# HC32F558 register map
File version: 1.0
CPU: CM4 r0p1, little endian, MPU, FPU, 4 interrupt priority bits
Registers are 32-bit, read-write, reset 0x0 unless marked. A register's access mark holds for its fields unless they carry their own. Offsets are from the block's base; [hi:lo] are bit positions; {n}, {i} and the like mark numbered series.

## RMU
Base 0x4004CC00
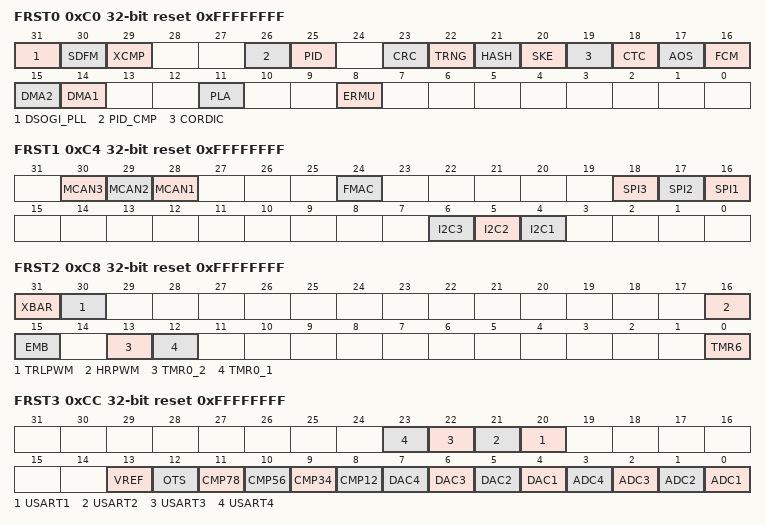
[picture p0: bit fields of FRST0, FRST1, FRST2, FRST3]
0xC0 FRST0 reset 0xFFFFFFFF
  [31] DSOGI_PLL, [30] SDFM, [29] XCMP, [26] PID_CMP, [25] PID, [23] CRC, [22] TRNG, [21] HASH, [20] SKE, [19] CORDIC, [18] CTC, [17] AOS, [16] FCM, [15] DMA2, [14] DMA1, [11] PLA, [8] ERMU
0xC4 FRST1 reset 0xFFFFFFFF
  [30] MCAN3, [29] MCAN2, [28] MCAN1, [24] FMAC, [18] SPI3, [17] SPI2, [16] SPI1, [6] I2C3, [5] I2C2, [4] I2C1
0xC8 FRST2 reset 0xFFFFFFFF
  [31] XBAR, [30] TRLPWM, [16] HRPWM, [15] EMB, [13] TMR0_2, [12] TMR0_1, [0] TMR6
0xCC FRST3 reset 0xFFFFFFFF
  [n+19] USART{n} (n=1..4), [13] VREF, [12] OTS, [11] CMP78, [10] CMP56, [9] CMP34, [8] CMP12, [n+3] DAC{n} (n=1..4), [n-1] ADC{n} (n=1..4)
0xF8 PRSTCR0 8-bit reset 0x40
  [5] LKUPREN
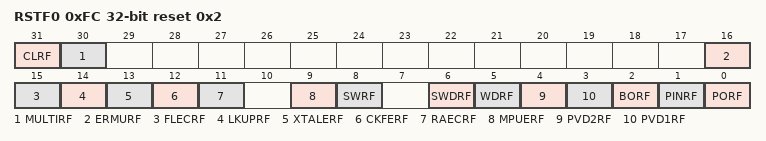
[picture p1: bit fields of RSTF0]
0xFC RSTF0 reset 0x2
  [31] CLRF, [30] MULTIRF, [16] ERMURF, [15] FLECRF, [14] LKUPRF, [13] XTALERF, [12] CKFERF, [11] RAECRF, [9] MPUERF, [8] SWRF, [6] SWDRF, [5] WDRF, [4] PVD2RF, [3] PVD1RF, [2] BORF, [1] PINRF, [0] PORF

## SKE
Base 0x4000E000
0x00 CTRL
  [0] START
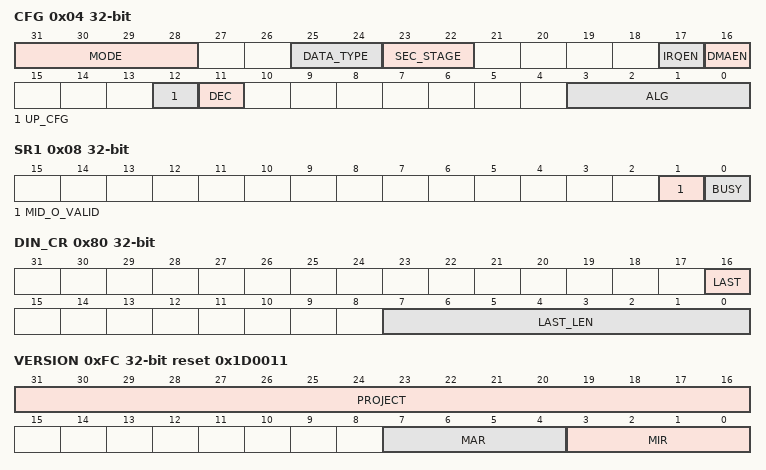
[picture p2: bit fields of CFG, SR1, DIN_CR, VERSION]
0x04 CFG
  [31:28] MODE, [25:24] DATA_TYPE, [23:22] SEC_STAGE, [17] IRQEN, [16] DMAEN, [12] UP_CFG, [11] DEC, [3:0] ALG
0x08 SR1
  [1] MID_O_VALID, [0] BUSY ro
0x0C SR2
  [0] CORE_DONE
{0xC+4i} KEY{i} wo (i=1..8)
0x60 AAD1
0x64 AAD2
0x68 CLEN1
0x6C CLEN2
{0x6C+4i} IV{i} (i=1..4)
0x80 DIN_CR
  [16] LAST, [7:0] LAST_LEN
{0x8C+4i} DIN{i} wo (i=1..4)
{0xAC+4i} DOUT{i} ro (i=1..4)
0xFC VERSION ro reset 0x1D0011
  [31:16] PROJECT, [7:4] MAR, [3:0] MIR
{0x19C+4i} MID_IV{i} (i=1..4)
{0x1AC+4i} MID_MAC{i} (i=1..4)
0x1C0 TOTAL_AAD1
0x1C4 TOTAL_AAD2
0x1C8 TOTAL_CLEN1
0x1CC TOTAL_CLEN2

## SPI1 — desc SPI
Base 0x4001C000
Same registers: SPI2 0x4001C400, SPI3 0x4001C800
0x00 DR
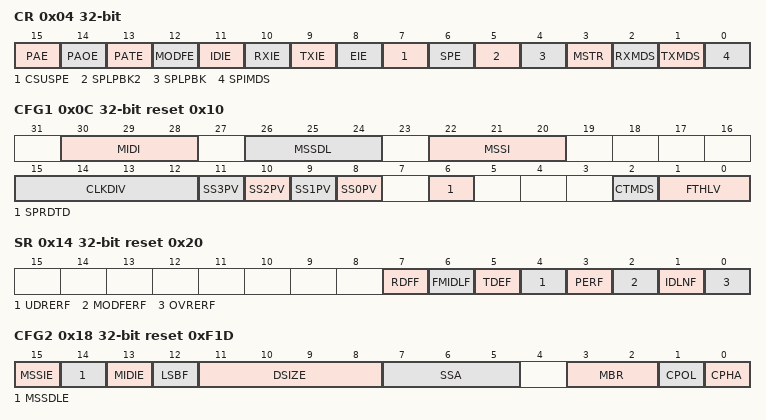
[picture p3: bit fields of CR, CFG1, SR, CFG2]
0x04 CR
  [15] PAE, [14] PAOE, [13] PATE, [12] MODFE, [11] IDIE, [10] RXIE, [9] TXIE, [8] EIE, [7] CSUSPE, [6] SPE, [5] SPLPBK2, [4] SPLPBK, [3] MSTR, [2] RXMDS, [1] TXMDS, [0] SPIMDS
0x0C CFG1 reset 0x10
  [30:28] MIDI, [26:24] MSSDL, [22:20] MSSI, [15:12] CLKDIV, [n+8] SS{n}PV (n=0..3), [6] SPRDTD, [2] CTMDS, [1:0] FTHLV
0x14 SR reset 0x20
  [7] RDFF ro, [6] FMIDLF ro, [5] TDEF ro, [4] UDRERF, [3] PERF, [2] MODFERF, [1] IDLNF ro, [0] OVRERF
0x18 CFG2 reset 0xF1D
  [15] MSSIE, [14] MSSDLE, [13] MIDIE, [12] LSBF, [11:8] DSIZE, [7:5] SSA, [3:2] MBR, [1] CPOL, [0] CPHA

## SRAMC
Base 0x40050800
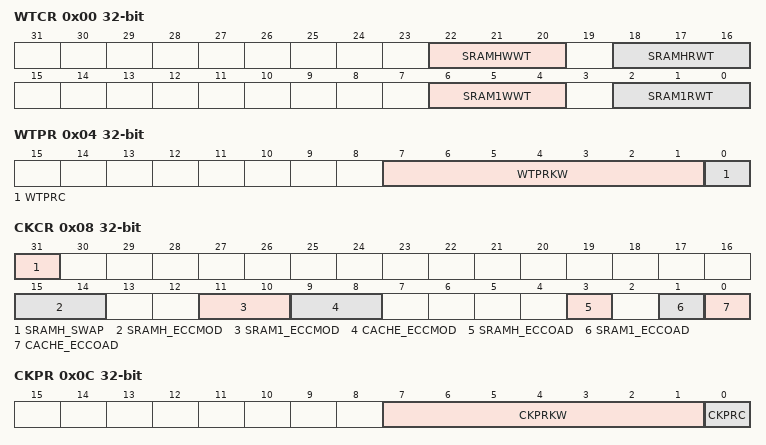
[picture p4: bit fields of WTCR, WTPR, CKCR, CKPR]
0x00 WTCR
  [22:20] SRAMHWWT, [18:16] SRAMHRWT, [6:4] SRAM1WWT, [2:0] SRAM1RWT
0x04 WTPR
  [7:1] WTPRKW, [0] WTPRC
0x08 CKCR
  [31] SRAMH_SWAP, [15:14] SRAMH_ECCMOD, [11:10] SRAM1_ECCMOD, [9:8] CACHE_ECCMOD, [3] SRAMH_ECCOAD, [1] SRAM1_ECCOAD, [0] CACHE_ECCOAD
0x0C CKPR
  [7:1] CKPRKW, [0] CKPRC
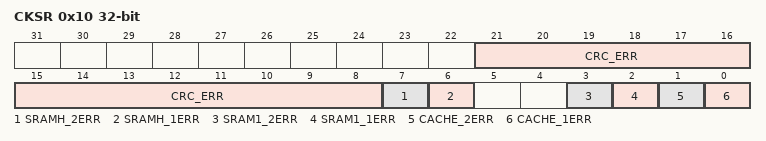
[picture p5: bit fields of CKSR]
0x10 CKSR
  [21:8] CRC_ERR, [7] SRAMH_2ERR, [6] SRAMH_1ERR, [3] SRAM1_2ERR, [2] SRAM1_1ERR, [1] CACHE_2ERR, [0] CACHE_1ERR
0x14 SRAM1_EIEN
  [0] EIEN
0x18 SRAM1_EIBIT0
0x1C SRAM1_EIBIT1
  [6:0] EIBIT
0x20 SRAM1_ECCERRADDR
  [16:0] ECCERRADDR
0x34 SRAMH_EIEN
  [0] EIEN
0x38 SRAMH_EIBIT0
0x3C SRAMH_EIBIT1
  [6:0] EIBIT
0x40 SRAMH_ECCERRADDR
  [14:0] ECCERRADDR
0x44 CACHE_EIEN
  [0] EIEN
{0x48+4i} CACHE_EIBIT{i} (i=0..3)
0x58 CACHE_EIBIT4
  [8:0] EIBIT
0x5C CACHE_ECCERRADDR
  [7:0] ECCERRADDR

## SWDT
Base 0x40049400
Same registers: WDT 0x40049000
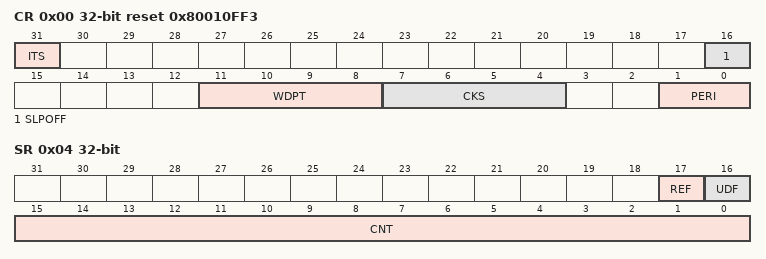
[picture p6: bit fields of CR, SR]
0x00 CR reset 0x80010FF3
  [31] ITS, [16] SLPOFF, [11:8] WDPT, [7:4] CKS, [1:0] PERI
0x04 SR
  [17] REF, [16] UDF, [15:0] CNT ro
0x08 RR
  [15:0] RF

## TMR01
Base 0x40024000
0x00 CNTAR
  [15:0] CNTA
0x04 CNTBR
  [15:0] CNTB
0x08 CMPAR reset 0xFFFF
  [15:0] CMPA
0x0C CMPBR reset 0xFFFF
  [15:0] CMPB
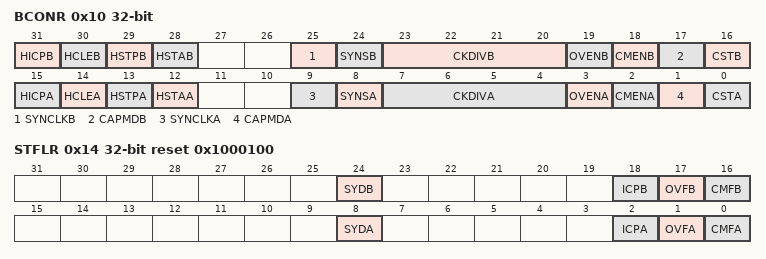
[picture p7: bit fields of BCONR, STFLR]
0x10 BCONR
  [31] HICPB, [30] HCLEB, [29] HSTPB, [28] HSTAB, [25] SYNCLKB, [24] SYNSB, [23:20] CKDIVB, [19] OVENB, [18] CMENB, [17] CAPMDB, [16] CSTB, [15] HICPA, [14] HCLEA, [13] HSTPA, [12] HSTAA, [9] SYNCLKA, [8] SYNSA, [7:4] CKDIVA, [3] OVENA, [2] CMENA, [1] CAPMDA, [0] CSTA
0x14 STFLR reset 0x1000100
  [24] SYDB, [18] ICPB, [17] OVFB, [16] CMFB, [8] SYDA, [2] ICPA, [1] OVFA, [0] CMFA

## TMR02
Base 0x40024400
Registers as TMR01; these are added or differ:
0x00 CNTAR
0x04 CNTBR
0x08 CMPAR reset 0xFFFFFFFF
0x0C CMPBR reset 0xFFFFFFFF
